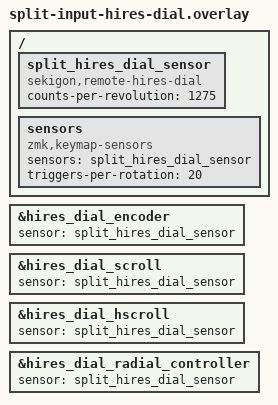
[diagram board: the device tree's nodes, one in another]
/ {
    /* Split HIRES events use sensor index 0; this device never emits local events. */
    split_hires_dial_sensor: split_hires_dial_sensor {
        compatible = "sekigon,remote-hires-dial";
        counts-per-revolution = <1275>;
    };

    sensors {
        compatible = "zmk,keymap-sensors";
        sensors = <&split_hires_dial_sensor>;
        triggers-per-rotation = <20>;
    };
};

&hires_dial_encoder {
    sensor = <&split_hires_dial_sensor>;
};

&hires_dial_scroll {
    sensor = <&split_hires_dial_sensor>;
};

&hires_dial_hscroll {
    sensor = <&split_hires_dial_sensor>;
};

&hires_dial_radial_controller {
    sensor = <&split_hires_dial_sensor>;
};
